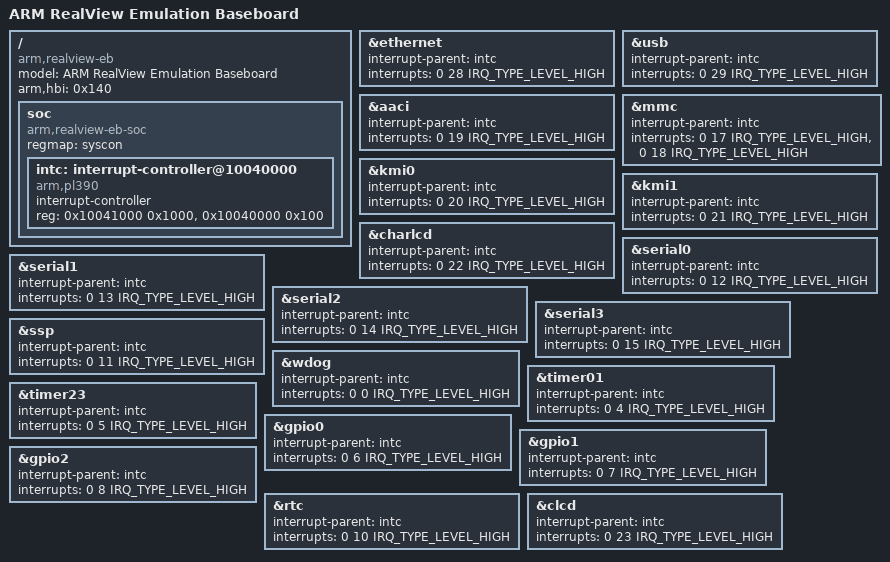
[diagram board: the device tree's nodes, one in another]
/dts-v1/;
#include <dt-bindings/interrupt-controller/irq.h>
#include <dt-bindings/gpio/gpio.h>
#include "arm-realview-eb.dtsi"
/ {
	model = "ARM RealView Emulation Baseboard";
	compatible = "arm,realview-eb";
	arm,hbi = <0x140>;
	soc {
		#address-cells = <1>;
		#size-cells = <1>;
		compatible = "arm,realview-eb-soc", "simple-bus";
		regmap = <&syscon>;
		ranges;
		intc: interrupt-controller@10040000 {
			compatible = "arm,pl390";
			#interrupt-cells = <3>;
			#address-cells = <1>;
			interrupt-controller;
			reg = <0x10041000 0x1000>,
			      <0x10040000 0x100>;
		};
	};
};
&ethernet {
	interrupt-parent = <&intc>;
	interrupts = <0 28 IRQ_TYPE_LEVEL_HIGH>;
};
&usb {
	interrupt-parent = <&intc>;
	interrupts = <0 29 IRQ_TYPE_LEVEL_HIGH>;
};
&aaci {
	interrupt-parent = <&intc>;
	interrupts = <0 19 IRQ_TYPE_LEVEL_HIGH>;
};
&mmc {
	interrupt-parent = <&intc>;
	interrupts = <0 17 IRQ_TYPE_LEVEL_HIGH>,
			<0 18 IRQ_TYPE_LEVEL_HIGH>;
};
&kmi0 {
	interrupt-parent = <&intc>;
	interrupts = <0 20 IRQ_TYPE_LEVEL_HIGH>;
};
&kmi1 {
	interrupt-parent = <&intc>;
	interrupts = <0 21 IRQ_TYPE_LEVEL_HIGH>;
};
&charlcd {
	interrupt-parent = <&intc>;
	interrupts = <0 22 IRQ_TYPE_LEVEL_HIGH>;
};
&serial0 {
	interrupt-parent = <&intc>;
	interrupts = <0 12 IRQ_TYPE_LEVEL_HIGH>;
};
&serial1 {
	interrupt-parent = <&intc>;
	interrupts = <0 13 IRQ_TYPE_LEVEL_HIGH>;
};
&serial2 {
	interrupt-parent = <&intc>;
	interrupts = <0 14 IRQ_TYPE_LEVEL_HIGH>;
};
&serial3 {
	interrupt-parent = <&intc>;
	interrupts = <0 15 IRQ_TYPE_LEVEL_HIGH>;
};
&ssp {
	interrupt-parent = <&intc>;
	interrupts = <0 11 IRQ_TYPE_LEVEL_HIGH>;
};
&wdog {
	interrupt-parent = <&intc>;
	interrupts = <0 0 IRQ_TYPE_LEVEL_HIGH>;
};
&timer01 {
	interrupt-parent = <&intc>;
	interrupts = <0 4 IRQ_TYPE_LEVEL_HIGH>;
};
&timer23 {
	interrupt-parent = <&intc>;
	interrupts = <0 5 IRQ_TYPE_LEVEL_HIGH>;
};
&gpio0 {
	interrupt-parent = <&intc>;
	interrupts = <0 6 IRQ_TYPE_LEVEL_HIGH>;
};
&gpio1 {
	interrupt-parent = <&intc>;
	interrupts = <0 7 IRQ_TYPE_LEVEL_HIGH>;
};
&gpio2 {
	interrupt-parent = <&intc>;
	interrupts = <0 8 IRQ_TYPE_LEVEL_HIGH>;
};
&rtc {
	interrupt-parent = <&intc>;
	interrupts = <0 10 IRQ_TYPE_LEVEL_HIGH>;
};
&clcd {
	interrupt-parent = <&intc>;
	interrupts = <0 23 IRQ_TYPE_LEVEL_HIGH>;
};
